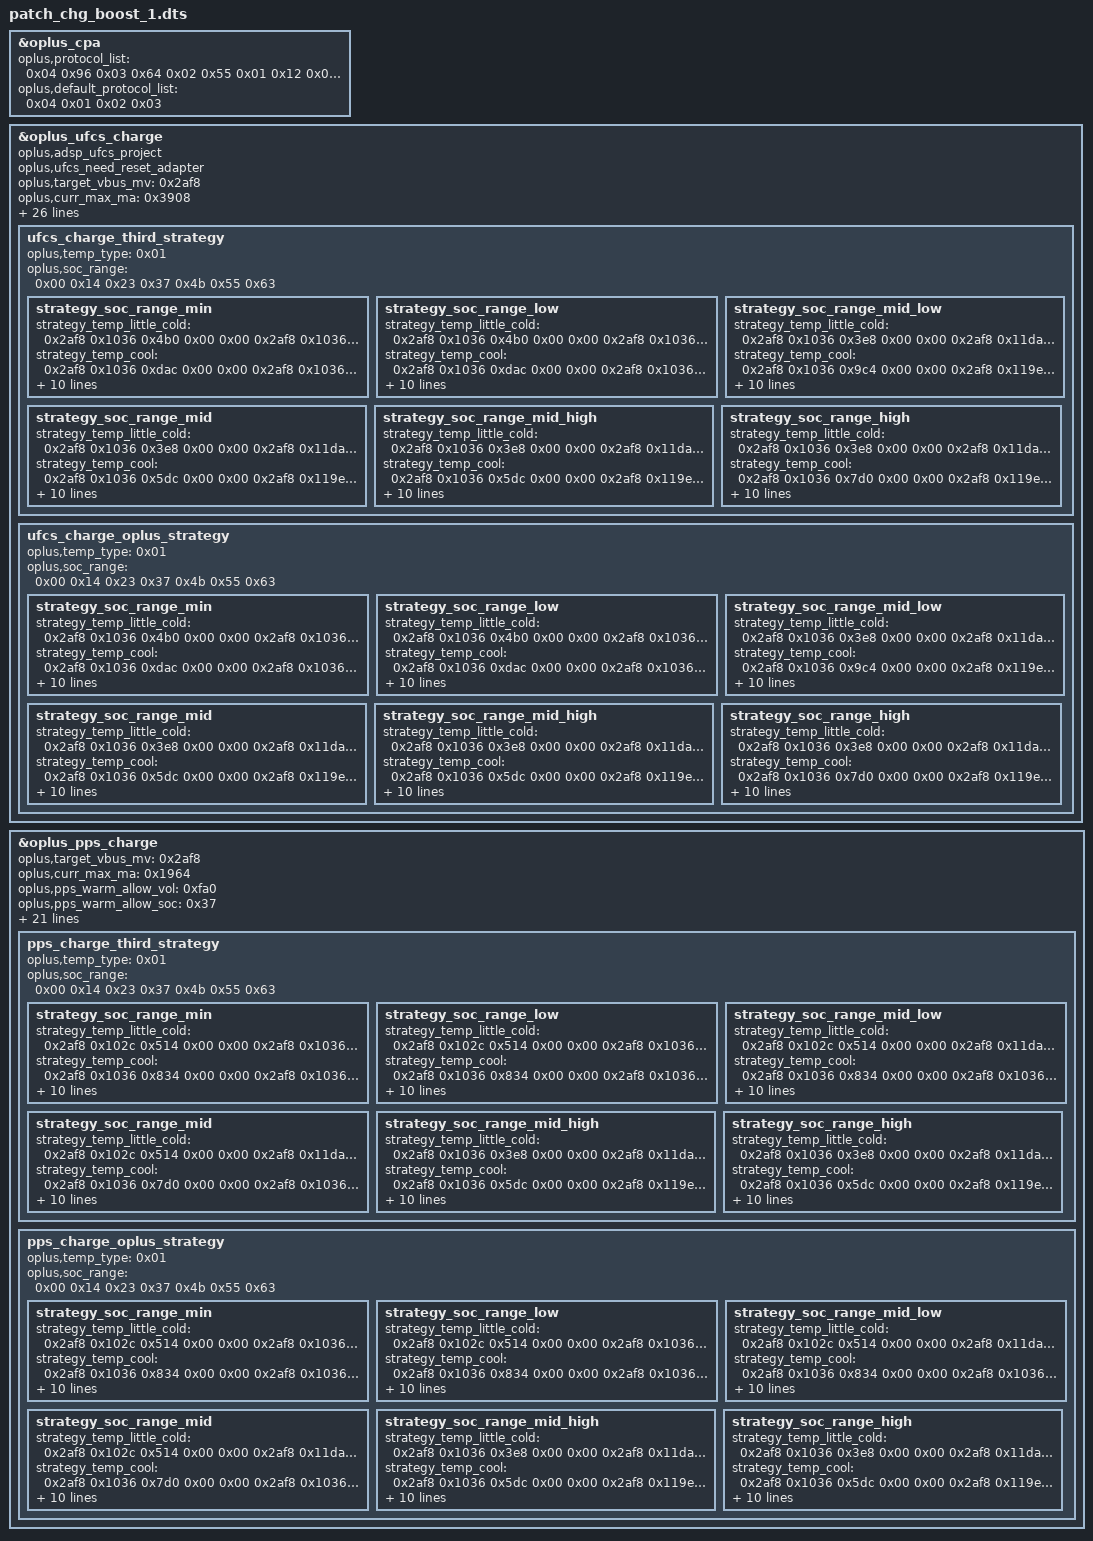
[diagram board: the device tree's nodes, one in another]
/dts-v1/;
/plugin/;

/ {
	fragment@0 {
		target = <&oplus_cpa>;
		__overlay__ {
			oplus,protocol_list = <0x04 0x96 0x03 0x64 0x02 0x55 0x01 0x12 0x05 0x12>;
			oplus,default_protocol_list = <0x04 0x01 0x02 0x03>;
		};
	};
	
	fragment@1 {
		target = <&oplus_ufcs_charge>;
		__overlay__ {
			oplus,adsp_ufcs_project;
			oplus,ufcs_need_reset_adapter;
			oplus,target_vbus_mv = <0x2af8>;
			oplus,curr_max_ma = <0x3908>;
			oplus,subboard_ntc_abnormal_current = <0x1c84>;
			oplus,ufcs_warm_allow_vol = <0xfa0>;
			oplus,ufcs_warm_allow_soc = <0x37>;
			oplus,ufcs_strategy_normal_current = <0x3908>;
			oplus,ufcs_over_high_or_low_current = <0x3908>;
			oplus,ufcs_timeout_third = <0x3a28>;
			oplus,ufcs_timeout_oplus = <0x3a28>;
			oplus,ufcs_ibat_over_third = <0x3908>;
			oplus,ufcs_ibat_over_oplus = <0x3908>;
			oplus,ufcs_ibus_over_oplus = <0x3778>;
			oplus,ufcs_full_cool_sw_vbat = <0x11f8>;
			oplus,ufcs_full_normal_sw_vbat = <0x11f8>;
			oplus,ufcs_full_normal_hw_vbat = <0x1202>;
			oplus,ufcs_full_ffc_vbat = <0x11bc>;
			oplus,ufcs_full_warm_vbat = <0x1022>;
			oplus,ufcs_full_cool_sw_vbat_third = <0x11f8>;
			oplus,ufcs_full_normal_sw_vbat_third = <0x11f8>;
			oplus,ufcs_full_normal_hw_vbat_third = <0x1202>;
			oplus,ufcs_current_change_timeout = <0x64>;
			oplus,ufcs_strategy_high_current = <0x1388 0xfa0 0xbb8 0x3908 0x1388 0xfa0>;
			oplus,ufcs_little_cool_high_temp = <0xd2>;
			oplus,curve_strategy_name = "pps_ufcs_curve_v2";
			oplus_spec,ufcs_high_soc = <0x63>;
			oplus,ufcs_charge_strategy_soc = <0x00 0x14 0x23 0x37 0x4b 0x55 0x63>;
			
			ufcs_charge_third_strategy {
				oplus,temp_type = <0x01>;
				oplus,soc_range = <0x00 0x14 0x23 0x37 0x4b 0x55 0x63>;
				
				strategy_soc_range_min {
					strategy_temp_little_cold = <0x2af8 0x1036 0x4b0 0x00 0x00 0x2af8 0x1036 0x3e8 0x00 0x00 0x2af8 0x11da 0x1f4 0x01 0x00>;
					strategy_temp_cool = <0x2af8 0x1036 0xdac 0x00 0x00 0x2af8 0x1036 0xbb8 0x00 0x00 0x2af8 0x119e 0x4b0 0x00 0x00 0x2af8 0x119e 0x3e8 0x00 0x00 0x2af8 0x11d0 0x258 0x00 0x00 0x2af8 0x11da 0x1f4 0x01 0x00>;
					strategy_temp_little_cool = <0x2af8 0x1036 0x1194 0x00 0x00 0x2af8 0x1036 0xdac 0x00 0x00 0x2af8 0x10ea 0xbb8 0x00 0x00 0x2af8 0x10ea 0x9c4 0x00 0x00 0x2af8 0x11d0 0x4b0 0x00 0x00 0x2af8 0x11d0 0x3e8 0x00 0x00 0x2af8 0x11da 0x2bc 0x01 0x00>;
					strategy_temp_little_cool_high = <0x2af8 0x1068 0x1964 0x00 0x00 0x2af8 0x1068 0x1770 0x00 0x00 0x2af8 0x1068 0x157c 0x00 0x00 0x2af8 0x1068 0x1194 0x00 0x00 0x2af8 0x10ea 0x1194 0x00 0x00 0x2af8 0x10ea 0xfa0 0x00 0x00 0x2af8 0x119e 0xc1c 0x00 0x00 0x2af8 0x119e 0xbb8 0x00 0x00 0x2af8 0x11d0 0xa28 0x00 0x00 0x2af8 0x11d0 0x9c4 0x00 0x00 0x2af8 0x11d0 0x7d0 0x00 0x00 0x2af8 0x11d0 0x5dc 0x00 0x00 0x2af8 0x11d0 0x3e8 0x00 0x00 0x2af8 0x11da 0x320 0x01 0x00>;
					strategy_temp_normal_low = <0x2af8 0x1054 0x238c 0x00 0x00 0x2af8 0x1054 0x238c 0x00 0x00 0x2af8 0x1054 0x238c 0x00 0x00 0x2af8 0x1086 0x238c 0x00 0x00 0x2af8 0x1086 0x2328 0x00 0x00 0x2af8 0x1086 0x2134 0x00 0x00 0x2af8 0x1108 0x1f40 0x00 0x00 0x2af8 0x1108 0x1b58 0x00 0x00 0x2af8 0x1108 0x1770 0x00 0x00 0x2af8 0x1108 0x157c 0x00 0x00 0x2af8 0x1180 0x1450 0x00 0x00 0x2af8 0x1180 0x1388 0x00 0x00 0x2af8 0x1180 0x1194 0x00 0x00 0x2af8 0x1180 0xfa0 0x00 0x00 0x2af8 0x11b2 0xf3c 0x00 0x00 0x2af8 0x11b2 0xdac 0x00 0x00 0x2af8 0x11d0 0xc1c 0x00 0x00 0x2af8 0x11d0 0xbb8 0x00 0x00 0x2af8 0x11d0 0x9c4 0x00 0x00 0x2af8 0x11d0 0x7d0 0x00 0x00 0x2af8 0x11d0 0x5dc 0x00 0x00 0x2af8 0x11da 0x578 0x01 0x00>;
					strategy_temp_normal_high = <0x2af8 0x1054 0x238c 0x00 0x00 0x2af8 0x1054 0x238c 0x00 0x00 0x2af8 0x1054 0x238c 0x00 0x00 0x2af8 0x1086 0x238c 0x00 0x00 0x2af8 0x1086 0x2134 0x00 0x00 0x2af8 0x1086 0x206c 0x00 0x00 0x2af8 0x1108 0x1f40 0x00 0x00 0x2af8 0x1108 0x1d4c 0x00 0x00 0x2af8 0x1108 0x1964 0x00 0x00 0x2af8 0x1108 0x157c 0x00 0x00 0x2af8 0x1180 0x1450 0x00 0x00 0x2af8 0x1180 0x1388 0x00 0x00 0x2af8 0x1180 0x1194 0x00 0x00 0x2af8 0x1180 0xfa0 0x00 0x00 0x2af8 0x11b2 0xf3c 0x00 0x00 0x2af8 0x11b2 0xdac 0x00 0x00 0x2af8 0x11d0 0xc1c 0x00 0x00 0x2af8 0x11d0 0xbb8 0x00 0x00 0x2af8 0x11d0 0x9c4 0x00 0x00 0x2af8 0x11d0 0x7d0 0x00 0x00 0x2af8 0x11da 0x76c 0x01 0x00>;
					strategy_temp_warm = <0x2af8 0x1018 0x578 0x00 0x00 0x2af8 0x1018 0x3e8 0x00 0x00 0x2af8 0x1022 0x1f4 0x01 0x00>;
				};
				
				strategy_soc_range_low {
					strategy_temp_little_cold = <0x2af8 0x1036 0x4b0 0x00 0x00 0x2af8 0x1036 0x3e8 0x00 0x00 0x2af8 0x11da 0x1f4 0x01 0x00>;
					strategy_temp_cool = <0x2af8 0x1036 0xdac 0x00 0x00 0x2af8 0x1036 0xdac 0x00 0x00 0x2af8 0x119e 0x4b0 0x00 0x00 0x2af8 0x119e 0x3e8 0x00 0x00 0x2af8 0x11d0 0x258 0x00 0x00 0x2af8 0x11da 0x1f4 0x01 0x00>;
					strategy_temp_little_cool = <0x2af8 0x1036 0xdac 0x00 0x00 0x2af8 0x1036 0xbb8 0x00 0x00 0x2af8 0x10ea 0x9c4 0x00 0x00 0x2af8 0x10ea 0x7d0 0x00 0x00 0x2af8 0x11d0 0x4b0 0x00 0x00 0x2af8 0x11d0 0x3e8 0x00 0x00 0x2af8 0x11da 0x2bc 0x01 0x00>;
					strategy_temp_little_cool_high = <0x2af8 0x1068 0x1d4c 0x00 0x00 0x2af8 0x1068 0x1964 0x00 0x00 0x2af8 0x1068 0x1770 0x00 0x00 0x2af8 0x1068 0x157c 0x00 0x00 0x2af8 0x10ea 0x1388 0x00 0x00 0x2af8 0x10ea 0x1194 0x00 0x00 0x2af8 0x119e 0xc1c 0x00 0x00 0x2af8 0x119e 0xbb8 0x00 0x00 0x2af8 0x11d0 0xa28 0x00 0x00 0x2af8 0x11d0 0x9c4 0x00 0x00 0x2af8 0x11d0 0x7d0 0x00 0x00 0x2af8 0x11d0 0x5dc 0x00 0x00 0x2af8 0x11d0 0x3e8 0x00 0x00 0x2af8 0x11da 0x320 0x01 0x00>;
					strategy_temp_normal_low = <0x2af8 0x1054 0x238c 0x00 0x00 0x2af8 0x1054 0x238c 0x00 0x00 0x2af8 0x1054 0x238c 0x00 0x00 0x2af8 0x1086 0x22c4 0x00 0x00 0x2af8 0x1108 0x1f40 0x00 0x00 0x2af8 0x1108 0x1b58 0x00 0x00 0x2af8 0x1108 0x1964 0x00 0x00 0x2af8 0x1108 0x157c 0x00 0x00 0x2af8 0x1180 0x1450 0x00 0x00 0x2af8 0x1180 0x1388 0x00 0x00 0x2af8 0x1180 0x1194 0x00 0x00 0x2af8 0x1180 0xfa0 0x00 0x00 0x2af8 0x11b2 0xf3c 0x00 0x00 0x2af8 0x11b2 0xdac 0x00 0x00 0x2af8 0x11d0 0xc1c 0x00 0x00 0x2af8 0x11d0 0xbb8 0x00 0x00 0x2af8 0x11d0 0x9c4 0x00 0x00 0x2af8 0x11d0 0x7d0 0x00 0x00 0x2af8 0x11d0 0x5dc 0x00 0x00 0x2af8 0x11da 0x578 0x01 0x00>;
					strategy_temp_normal_high = <0x2af8 0x1054 0x238c 0x00 0x00 0x2af8 0x1054 0x238c 0x00 0x00 0x2af8 0x1054 0x2134 0x00 0x00 0x2af8 0x1086 0x2134 0x00 0x00 0x2af8 0x1086 0x2134 0x00 0x00 0x2af8 0x1086 0x1f40 0x00 0x00 0x2af8 0x1108 0x1d4c 0x00 0x00 0x2af8 0x1108 0x1a2c 0x00 0x00 0x2af8 0x1108 0x1964 0x00 0x00 0x2af8 0x1108 0x157c 0x00 0x00 0x2af8 0x1180 0x1450 0x00 0x00 0x2af8 0x1180 0x1388 0x00 0x00 0x2af8 0x1180 0x1194 0x00 0x00 0x2af8 0x1180 0xfa0 0x00 0x00 0x2af8 0x11b2 0xf3c 0x00 0x00 0x2af8 0x11b2 0xdac 0x00 0x00 0x2af8 0x11d0 0xc1c 0x00 0x00 0x2af8 0x11d0 0xbb8 0x00 0x00 0x2af8 0x11d0 0x9c4 0x00 0x00 0x2af8 0x11d0 0x7d0 0x00 0x00 0x2af8 0x11da 0x76c 0x01 0x00>;
					strategy_temp_warm = <0x2af8 0x1018 0x578 0x00 0x00 0x2af8 0x1018 0x3e8 0x00 0x00 0x2af8 0x1022 0x1f4 0x01 0x00>;
				};
				
				strategy_soc_range_mid_low {
					strategy_temp_little_cold = <0x2af8 0x1036 0x3e8 0x00 0x00 0x2af8 0x11da 0x1f4 0x01 0x00>;
					strategy_temp_cool = <0x2af8 0x1036 0x9c4 0x00 0x00 0x2af8 0x119e 0x4b0 0x00 0x00 0x2af8 0x119e 0x3e8 0x00 0x00 0x2af8 0x11d0 0x258 0x00 0x00 0x2af8 0x11da 0x1f4 0x01 0x00>;
					strategy_temp_little_cool = <0x2af8 0x1036 0x1194 0x00 0x00 0x2af8 0x1036 0x1194 0x00 0x00 0x2af8 0x10ea 0x7d0 0x00 0x00 0x2af8 0x10ea 0x5dc 0x00 0x00 0x2af8 0x11d0 0x4b0 0x00 0x00 0x2af8 0x11d0 0x3e8 0x00 0x00 0x2af8 0x11da 0x2bc 0x01 0x00>;
					strategy_temp_little_cool_high = <0x2af8 0x1068 0x1964 0x00 0x00 0x2af8 0x1068 0x1964 0x00 0x00 0x2af8 0x1068 0x157c 0x00 0x00 0x2af8 0x1068 0x1194 0x00 0x00 0x2af8 0x10ea 0xf3c 0x00 0x00 0x2af8 0x10ea 0xdac 0x00 0x00 0x2af8 0x119e 0xc1c 0x00 0x00 0x2af8 0x119e 0xbb8 0x00 0x00 0x2af8 0x11d0 0xa28 0x00 0x00 0x2af8 0x11d0 0x9c4 0x00 0x00 0x2af8 0x11d0 0x7d0 0x00 0x00 0x2af8 0x11d0 0x5dc 0x00 0x00 0x2af8 0x11d0 0x3e8 0x00 0x00 0x2af8 0x11da 0x320 0x01 0x00>;
					strategy_temp_normal_low = <0x2af8 0x1054 0x238c 0x00 0x00 0x2af8 0x1054 0x238c 0x00 0x00 0x2af8 0x1054 0x238c 0x00 0x00 0x2af8 0x1086 0x2134 0x00 0x00 0x2af8 0x1086 0x2134 0x00 0x00 0x2af8 0x1086 0x1f40 0x00 0x00 0x2af8 0x1108 0x1e78 0x00 0x00 0x2af8 0x1108 0x1ce8 0x00 0x00 0x2af8 0x1108 0x1964 0x00 0x00 0x2af8 0x1108 0x1770 0x00 0x00 0x2af8 0x1180 0x1450 0x00 0x00 0x2af8 0x1180 0x1388 0x00 0x00 0x2af8 0x1180 0x1194 0x00 0x00 0x2af8 0x1180 0xfa0 0x00 0x00 0x2af8 0x11b2 0xf3c 0x00 0x00 0x2af8 0x11b2 0xdac 0x00 0x00 0x2af8 0x11d0 0xc1c 0x00 0x00 0x2af8 0x11d0 0xbb8 0x00 0x00 0x2af8 0x11d0 0x9c4 0x00 0x00 0x2af8 0x11d0 0x7d0 0x00 0x00 0x2af8 0x11d0 0x5dc 0x00 0x00 0x2af8 0x11da 0x578 0x01 0x00>;
					strategy_temp_normal_high = <0x2af8 0x1054 0x238c 0x00 0x00 0x2af8 0x1054 0x238c 0x00 0x00 0x2af8 0x1054 0x238c 0x00 0x00 0x2af8 0x1086 0x238c 0x00 0x00 0x2af8 0x1086 0x2260 0x00 0x00 0x2af8 0x1086 0x2134 0x00 0x00 0x2af8 0x1108 0x1d4c 0x00 0x00 0x2af8 0x1108 0x1b58 0x00 0x00 0x2af8 0x1108 0x1964 0x00 0x00 0x2af8 0x1108 0x16a8 0x00 0x00 0x2af8 0x1180 0x1450 0x00 0x00 0x2af8 0x1180 0x1388 0x00 0x00 0x2af8 0x1180 0x1194 0x00 0x00 0x2af8 0x1180 0xfa0 0x00 0x00 0x2af8 0x11b2 0xf3c 0x00 0x00 0x2af8 0x11b2 0xdac 0x00 0x00 0x2af8 0x11d0 0xc1c 0x00 0x00 0x2af8 0x11d0 0xbb8 0x00 0x00 0x2af8 0x11d0 0x9c4 0x00 0x00 0x2af8 0x11d0 0x7d0 0x00 0x00 0x2af8 0x11da 0x76c 0x01 0x00>;
					strategy_temp_warm = <0x2af8 0x1018 0x578 0x00 0x00 0x2af8 0x1018 0x3e8 0x00 0x00 0x2af8 0x1022 0x1f4 0x01 0x00>;
				};
				
				strategy_soc_range_mid {
					strategy_temp_little_cold = <0x2af8 0x1036 0x3e8 0x00 0x00 0x2af8 0x11da 0x1f4 0x01 0x00>;
					strategy_temp_cool = <0x2af8 0x1036 0x5dc 0x00 0x00 0x2af8 0x119e 0x4b0 0x00 0x00 0x2af8 0x119e 0x3e8 0x00 0x00 0x2af8 0x11d0 0x258 0x00 0x00 0x2af8 0x11da 0x1f4 0x01 0x00>;
					strategy_temp_little_cool = <0x2af8 0x1036 0xa28 0x00 0x00 0x2af8 0x1036 0x9c4 0x00 0x00 0x2af8 0x10ea 0x7d0 0x00 0x00 0x2af8 0x10ea 0x5dc 0x00 0x00 0x2af8 0x11d0 0x4b0 0x00 0x00 0x2af8 0x11d0 0x3e8 0x00 0x00 0x2af8 0x11da 0x2bc 0x01 0x00>;
					strategy_temp_little_cool_high = <0x2af8 0x1068 0x1d4c 0x00 0x00 0x2af8 0x1086 0x1c84 0x00 0x00 0x2af8 0x1108 0x1c20 0x00 0x00 0x2af8 0x1108 0x1b58 0x00 0x00 0x2af8 0x1108 0x1964 0x00 0x00 0x2af8 0x1108 0x16a8 0x00 0x00 0x2af8 0x10ea 0x1194 0x00 0x00 0x2af8 0x10ea 0x1068 0x00 0x00 0x2af8 0x119e 0xc1c 0x00 0x00 0x2af8 0x119e 0xbb8 0x00 0x00 0x2af8 0x11d0 0xa28 0x00 0x00 0x2af8 0x11d0 0x9c4 0x00 0x00 0x2af8 0x11d0 0x7d0 0x00 0x00 0x2af8 0x11d0 0x5dc 0x00 0x00 0x2af8 0x11d0 0x3e8 0x00 0x00 0x2af8 0x11da 0x320 0x01 0x00>;
					strategy_temp_normal_low = <0x2af8 0x1068 0x1d4c 0x00 0x00 0x2af8 0x1086 0x1c84 0x00 0x00 0x2af8 0x1108 0x1c20 0x00 0x00 0x2af8 0x1108 0x1b58 0x00 0x00 0x2af8 0x1108 0x1964 0x00 0x00 0x2af8 0x1108 0x1770 0x00 0x00 0x2af8 0x10ea 0x157c 0x00 0x00 0x2af8 0x10ea 0x14b4 0x00 0x00 0x2af8 0x1180 0x1388 0x00 0x00 0x2af8 0x1180 0x10cc 0x00 0x00 0x2af8 0x11b2 0xf3c 0x00 0x00 0x2af8 0x11b2 0xf3c 0x00 0x00 0x2af8 0x11d0 0xdac 0x00 0x00 0x2af8 0x11d0 0xbb8 0x00 0x00 0x2af8 0x11d0 0x9c4 0x00 0x00 0x2af8 0x11d0 0x7d0 0x00 0x00 0x2af8 0x11d0 0x5dc 0x00 0x00 0x2af8 0x11da 0x578 0x01 0x00>;
					strategy_temp_normal_high = <0x2af8 0x1108 0x1964 0x00 0x00 0x2af8 0x1108 0x1770 0x00 0x00 0x2af8 0x10ea 0x157c 0x00 0x00 0x2af8 0x10ea 0x14b4 0x00 0x00 0x2af8 0x1180 0x1388 0x00 0x00 0x2af8 0x1180 0x1194 0x00 0x00 0x2af8 0x1180 0xfa0 0x00 0x00 0x2af8 0x11b2 0xf3c 0x00 0x00 0x2af8 0x11b2 0xdac 0x00 0x00 0x2af8 0x11d0 0xc1c 0x00 0x00 0x2af8 0x11d0 0xbb8 0x00 0x00 0x2af8 0x11d0 0x9c4 0x00 0x00 0x2af8 0x11d0 0x7d0 0x00 0x00 0x2af8 0x11da 0x76c 0x01 0x00>;
					strategy_temp_warm = <0x2af8 0x1022 0x3e8 0x01 0x00>;
				};
				
				strategy_soc_range_mid_high {
					strategy_temp_little_cold = <0x2af8 0x1036 0x3e8 0x00 0x00 0x2af8 0x11da 0x1f4 0x01 0x00>;
					strategy_temp_cool = <0x2af8 0x1036 0x5dc 0x00 0x00 0x2af8 0x119e 0x4b0 0x00 0x00 0x2af8 0x119e 0x3e8 0x00 0x00 0x2af8 0x11d0 0x258 0x00 0x00 0x2af8 0x11da 0x1f4 0x01 0x00>;
					strategy_temp_little_cool = <0x2af8 0x1036 0xbb8 0x00 0x00 0x2af8 0x1036 0xbb8 0x00 0x00 0x2af8 0x10ea 0x9c4 0x00 0x00 0x2af8 0x10ea 0x7d0 0x00 0x00 0x2af8 0x11d0 0x4b0 0x00 0x00 0x2af8 0x11d0 0x3e8 0x00 0x00 0x2af8 0x11da 0x2bc 0x01 0x00>;
					strategy_temp_little_cool_high = <0x2af8 0x119e 0xdac 0x00 0x00 0x2af8 0x11d0 0xaf0 0x00 0x00 0x2af8 0x11d0 0xa28 0x00 0x00 0x2af8 0x11d0 0x898 0x00 0x00 0x2af8 0x11d0 0x5dc 0x00 0x00 0x2af8 0x11d0 0x3e8 0x00 0x00 0x2af8 0x11da 0x320 0x01 0x00>;
					strategy_temp_normal_low = <0x2af8 0x11b2 0xe10 0x00 0x00 0x2af8 0x11d0 0xd48 0x00 0x00 0x2af8 0x11d0 0xc80 0x00 0x00 0x2af8 0x11d0 0x9c4 0x00 0x00 0x2af8 0x11d0 0x7d0 0x00 0x00 0x2af8 0x11d0 0x5dc 0x00 0x00 0x2af8 0x11da 0x578 0x01 0x00>;
					strategy_temp_normal_high = <0x2af8 0x11b2 0xce4 0x00 0x00 0x2af8 0x11d0 0xc1c 0x00 0x00 0x2af8 0x11d0 0xbb8 0x00 0x00 0x2af8 0x11d0 0x9c4 0x00 0x00 0x2af8 0x11d0 0x7d0 0x00 0x00 0x2af8 0x11da 0x76c 0x01 0x00>;
					strategy_temp_warm = <0x2af8 0x1022 0x3e8 0x01 0x00>;
				};
				
				strategy_soc_range_high {
					strategy_temp_little_cold = <0x2af8 0x1036 0x3e8 0x00 0x00 0x2af8 0x11da 0x1f4 0x01 0x00>;
					strategy_temp_cool = <0x2af8 0x1036 0x7d0 0x00 0x00 0x2af8 0x119e 0x7d0 0x00 0x00 0x2af8 0x119e 0x5dc 0x00 0x00 0x2af8 0x11d0 0x514 0x00 0x00 0x2af8 0x11da 0x3e8 0x01 0x00>;
					strategy_temp_little_cool = <0x2af8 0x10ea 0x834 0x00 0x00 0x2af8 0x11d0 0x7d0 0x00 0x00 0x2af8 0x11d0 0x44c 0x00 0x00 0x2af8 0x11da 0x3e8 0x01 0x00>;
					strategy_temp_little_cool_high = <0x2af8 0x11d0 0x834 0x00 0x00 0x2af8 0x11d0 0x7d0 0x00 0x00 0x2af8 0x11da 0x3e8 0x01 0x00>;
					strategy_temp_normal_low = <0x2af8 0x11d0 0x834 0x00 0x00 0x2af8 0x11d0 0x7d0 0x00 0x00 0x2af8 0x11da 0x3e8 0x01 0x00>;
					strategy_temp_normal_high = <0x2af8 0x11d0 0x7d0 0x00 0x00 0x2af8 0x11da 0x76c 0x01 0x00>;
					strategy_temp_warm = <0x2af8 0x1022 0x3e8 0x01 0x00>;
				};
			};
			
			ufcs_charge_oplus_strategy {
				oplus,temp_type = <0x01>;
				oplus,soc_range = <0x00 0x14 0x23 0x37 0x4b 0x55 0x63>;
				
				strategy_soc_range_min {
					strategy_temp_little_cold = <0x2af8 0x1036 0x4b0 0x00 0x00 0x2af8 0x1036 0x3e8 0x00 0x00 0x2af8 0x11da 0x1f4 0x01 0x00>;
					strategy_temp_cool = <0x2af8 0x1036 0xdac 0x00 0x00 0x2af8 0x1036 0xbb8 0x00 0x00 0x2af8 0x119e 0x4b0 0x00 0x00 0x2af8 0x119e 0x3e8 0x00 0x00 0x2af8 0x11d0 0x258 0x00 0x00 0x2af8 0x11da 0x1f4 0x01 0x00>;
					strategy_temp_little_cool = <0x2af8 0x1036 0x1194 0x00 0x00 0x2af8 0x1036 0xdac 0x00 0x00 0x2af8 0x10ea 0xbb8 0x00 0x00 0x2af8 0x10ea 0x9c4 0x00 0x00 0x2af8 0x11d0 0x4b0 0x00 0x00 0x2af8 0x11d0 0x3e8 0x00 0x00 0x2af8 0x11da 0x2bc 0x01 0x00>;
					strategy_temp_little_cool_high = <0x2af8 0x1068 0x1964 0x00 0x00 0x2af8 0x1068 0x1770 0x00 0x00 0x2af8 0x1068 0x157c 0x00 0x00 0x2af8 0x1068 0x1194 0x00 0x00 0x2af8 0x10ea 0x1194 0x00 0x00 0x2af8 0x10ea 0xfa0 0x00 0x00 0x2af8 0x119e 0xc1c 0x00 0x00 0x2af8 0x119e 0xbb8 0x00 0x00 0x2af8 0x11d0 0xa28 0x00 0x00 0x2af8 0x11d0 0x9c4 0x00 0x00 0x2af8 0x11d0 0x7d0 0x00 0x00 0x2af8 0x11d0 0x5dc 0x00 0x00 0x2af8 0x11d0 0x3e8 0x00 0x00 0x2af8 0x11da 0x320 0x01 0x00>;
					strategy_temp_normal_low = <0x2af8 0x1054 0x238c 0x00 0x00 0x2af8 0x1054 0x238c 0x00 0x00 0x2af8 0x1054 0x238c 0x00 0x00 0x2af8 0x1086 0x238c 0x00 0x00 0x2af8 0x1086 0x2328 0x00 0x00 0x2af8 0x1086 0x2134 0x00 0x00 0x2af8 0x1108 0x1f40 0x00 0x00 0x2af8 0x1108 0x1b58 0x00 0x00 0x2af8 0x1108 0x1770 0x00 0x00 0x2af8 0x1108 0x157c 0x00 0x00 0x2af8 0x1180 0x1450 0x00 0x00 0x2af8 0x1180 0x1388 0x00 0x00 0x2af8 0x1180 0x1194 0x00 0x00 0x2af8 0x1180 0xfa0 0x00 0x00 0x2af8 0x11b2 0xf3c 0x00 0x00 0x2af8 0x11b2 0xdac 0x00 0x00 0x2af8 0x11d0 0xc1c 0x00 0x00 0x2af8 0x11d0 0xbb8 0x00 0x00 0x2af8 0x11d0 0x9c4 0x00 0x00 0x2af8 0x11d0 0x7d0 0x00 0x00 0x2af8 0x11d0 0x5dc 0x00 0x00 0x2af8 0x11da 0x578 0x01 0x00>;
					strategy_temp_normal_high = <0x2af8 0x1054 0x238c 0x00 0x00 0x2af8 0x1054 0x238c 0x00 0x00 0x2af8 0x1054 0x238c 0x00 0x00 0x2af8 0x1086 0x238c 0x00 0x00 0x2af8 0x1086 0x2134 0x00 0x00 0x2af8 0x1086 0x206c 0x00 0x00 0x2af8 0x1108 0x1f40 0x00 0x00 0x2af8 0x1108 0x1d4c 0x00 0x00 0x2af8 0x1108 0x1964 0x00 0x00 0x2af8 0x1108 0x157c 0x00 0x00 0x2af8 0x1180 0x1450 0x00 0x00 0x2af8 0x1180 0x1388 0x00 0x00 0x2af8 0x1180 0x1194 0x00 0x00 0x2af8 0x1180 0xfa0 0x00 0x00 0x2af8 0x11b2 0xf3c 0x00 0x00 0x2af8 0x11b2 0xdac 0x00 0x00 0x2af8 0x11d0 0xc1c 0x00 0x00 0x2af8 0x11d0 0xbb8 0x00 0x00 0x2af8 0x11d0 0x9c4 0x00 0x00 0x2af8 0x11d0 0x7d0 0x00 0x00 0x2af8 0x11da 0x76c 0x01 0x00>;
					strategy_temp_warm = <0x2af8 0x1018 0x578 0x00 0x00 0x2af8 0x1018 0x3e8 0x00 0x00 0x2af8 0x1022 0x1f4 0x01 0x00>;
				};
				
				strategy_soc_range_low {
					strategy_temp_little_cold = <0x2af8 0x1036 0x4b0 0x00 0x00 0x2af8 0x1036 0x3e8 0x00 0x00 0x2af8 0x11da 0x1f4 0x01 0x00>;
					strategy_temp_cool = <0x2af8 0x1036 0xdac 0x00 0x00 0x2af8 0x1036 0xdac 0x00 0x00 0x2af8 0x119e 0x4b0 0x00 0x00 0x2af8 0x119e 0x3e8 0x00 0x00 0x2af8 0x11d0 0x258 0x00 0x00 0x2af8 0x11da 0x1f4 0x01 0x00>;
					strategy_temp_little_cool = <0x2af8 0x1036 0xdac 0x00 0x00 0x2af8 0x1036 0xbb8 0x00 0x00 0x2af8 0x10ea 0x9c4 0x00 0x00 0x2af8 0x10ea 0x7d0 0x00 0x00 0x2af8 0x11d0 0x4b0 0x00 0x00 0x2af8 0x11d0 0x3e8 0x00 0x00 0x2af8 0x11da 0x2bc 0x01 0x00>;
					strategy_temp_little_cool_high = <0x2af8 0x1068 0x1d4c 0x00 0x00 0x2af8 0x1068 0x1964 0x00 0x00 0x2af8 0x1068 0x1770 0x00 0x00 0x2af8 0x1068 0x157c 0x00 0x00 0x2af8 0x10ea 0x1388 0x00 0x00 0x2af8 0x10ea 0x1194 0x00 0x00 0x2af8 0x119e 0xc1c 0x00 0x00 0x2af8 0x119e 0xbb8 0x00 0x00 0x2af8 0x11d0 0xa28 0x00 0x00 0x2af8 0x11d0 0x9c4 0x00 0x00 0x2af8 0x11d0 0x7d0 0x00 0x00 0x2af8 0x11d0 0x5dc 0x00 0x00 0x2af8 0x11d0 0x3e8 0x00 0x00 0x2af8 0x11da 0x320 0x01 0x00>;
					strategy_temp_normal_low = <0x2af8 0x1054 0x238c 0x00 0x00 0x2af8 0x1054 0x238c 0x00 0x00 0x2af8 0x1054 0x238c 0x00 0x00 0x2af8 0x1086 0x22c4 0x00 0x00 0x2af8 0x1108 0x1f40 0x00 0x00 0x2af8 0x1108 0x1b58 0x00 0x00 0x2af8 0x1108 0x1964 0x00 0x00 0x2af8 0x1108 0x157c 0x00 0x00 0x2af8 0x1180 0x1450 0x00 0x00 0x2af8 0x1180 0x1388 0x00 0x00 0x2af8 0x1180 0x1194 0x00 0x00 0x2af8 0x1180 0xfa0 0x00 0x00 0x2af8 0x11b2 0xf3c 0x00 0x00 0x2af8 0x11b2 0xdac 0x00 0x00 0x2af8 0x11d0 0xc1c 0x00 0x00 0x2af8 0x11d0 0xbb8 0x00 0x00 0x2af8 0x11d0 0x9c4 0x00 0x00 0x2af8 0x11d0 0x7d0 0x00 0x00 0x2af8 0x11d0 0x5dc 0x00 0x00 0x2af8 0x11da 0x578 0x01 0x00>;
					strategy_temp_normal_high = <0x2af8 0x1054 0x238c 0x00 0x00 0x2af8 0x1054 0x238c 0x00 0x00 0x2af8 0x1054 0x2134 0x00 0x00 0x2af8 0x1086 0x2134 0x00 0x00 0x2af8 0x1086 0x2134 0x00 0x00 0x2af8 0x1086 0x1f40 0x00 0x00 0x2af8 0x1108 0x1d4c 0x00 0x00 0x2af8 0x1108 0x1a2c 0x00 0x00 0x2af8 0x1108 0x1964 0x00 0x00 0x2af8 0x1108 0x157c 0x00 0x00 0x2af8 0x1180 0x1450 0x00 0x00 0x2af8 0x1180 0x1388 0x00 0x00 0x2af8 0x1180 0x1194 0x00 0x00 0x2af8 0x1180 0xfa0 0x00 0x00 0x2af8 0x11b2 0xf3c 0x00 0x00 0x2af8 0x11b2 0xdac 0x00 0x00 0x2af8 0x11d0 0xc1c 0x00 0x00 0x2af8 0x11d0 0xbb8 0x00 0x00 0x2af8 0x11d0 0x9c4 0x00 0x00 0x2af8 0x11d0 0x7d0 0x00 0x00 0x2af8 0x11da 0x76c 0x01 0x00>;
					strategy_temp_warm = <0x2af8 0x1018 0x578 0x00 0x00 0x2af8 0x1018 0x3e8 0x00 0x00 0x2af8 0x1022 0x1f4 0x01 0x00>;
				};
				
				strategy_soc_range_mid_low {
					strategy_temp_little_cold = <0x2af8 0x1036 0x3e8 0x00 0x00 0x2af8 0x11da 0x1f4 0x01 0x00>;
					strategy_temp_cool = <0x2af8 0x1036 0x9c4 0x00 0x00 0x2af8 0x119e 0x4b0 0x00 0x00 0x2af8 0x119e 0x3e8 0x00 0x00 0x2af8 0x11d0 0x258 0x00 0x00 0x2af8 0x11da 0x1f4 0x01 0x00>;
					strategy_temp_little_cool = <0x2af8 0x1036 0x1194 0x00 0x00 0x2af8 0x1036 0x1194 0x00 0x00 0x2af8 0x10ea 0x7d0 0x00 0x00 0x2af8 0x10ea 0x5dc 0x00 0x00 0x2af8 0x11d0 0x4b0 0x00 0x00 0x2af8 0x11d0 0x3e8 0x00 0x00 0x2af8 0x11da 0x2bc 0x01 0x00>;
					strategy_temp_little_cool_high = <0x2af8 0x1068 0x1964 0x00 0x00 0x2af8 0x1068 0x1964 0x00 0x00 0x2af8 0x1068 0x157c 0x00 0x00 0x2af8 0x1068 0x1194 0x00 0x00 0x2af8 0x10ea 0xf3c 0x00 0x00 0x2af8 0x10ea 0xdac 0x00 0x00 0x2af8 0x119e 0xc1c 0x00 0x00 0x2af8 0x119e 0xbb8 0x00 0x00 0x2af8 0x11d0 0xa28 0x00 0x00 0x2af8 0x11d0 0x9c4 0x00 0x00 0x2af8 0x11d0 0x7d0 0x00 0x00 0x2af8 0x11d0 0x5dc 0x00 0x00 0x2af8 0x11d0 0x3e8 0x00 0x00 0x2af8 0x11da 0x320 0x01 0x00>;
					strategy_temp_normal_low = <0x2af8 0x1054 0x238c 0x00 0x00 0x2af8 0x1054 0x238c 0x00 0x00 0x2af8 0x1054 0x238c 0x00 0x00 0x2af8 0x1086 0x2134 0x00 0x00 0x2af8 0x1086 0x2134 0x00 0x00 0x2af8 0x1086 0x1f40 0x00 0x00 0x2af8 0x1108 0x1e78 0x00 0x00 0x2af8 0x1108 0x1ce8 0x00 0x00 0x2af8 0x1108 0x1964 0x00 0x00 0x2af8 0x1108 0x1770 0x00 0x00 0x2af8 0x1180 0x1450 0x00 0x00 0x2af8 0x1180 0x1388 0x00 0x00 0x2af8 0x1180 0x1194 0x00 0x00 0x2af8 0x1180 0xfa0 0x00 0x00 0x2af8 0x11b2 0xf3c 0x00 0x00 0x2af8 0x11b2 0xdac 0x00 0x00 0x2af8 0x11d0 0xc1c 0x00 0x00 0x2af8 0x11d0 0xbb8 0x00 0x00 0x2af8 0x11d0 0x9c4 0x00 0x00 0x2af8 0x11d0 0x7d0 0x00 0x00 0x2af8 0x11d0 0x5dc 0x00 0x00 0x2af8 0x11da 0x578 0x01 0x00>;
					strategy_temp_normal_high = <0x2af8 0x1054 0x238c 0x00 0x00 0x2af8 0x1054 0x238c 0x00 0x00 0x2af8 0x1054 0x238c 0x00 0x00 0x2af8 0x1086 0x238c 0x00 0x00 0x2af8 0x1086 0x2260 0x00 0x00 0x2af8 0x1086 0x2134 0x00 0x00 0x2af8 0x1108 0x1d4c 0x00 0x00 0x2af8 0x1108 0x1b58 0x00 0x00 0x2af8 0x1108 0x1964 0x00 0x00 0x2af8 0x1108 0x16a8 0x00 0x00 0x2af8 0x1180 0x1450 0x00 0x00 0x2af8 0x1180 0x1388 0x00 0x00 0x2af8 0x1180 0x1194 0x00 0x00 0x2af8 0x1180 0xfa0 0x00 0x00 0x2af8 0x11b2 0xf3c 0x00 0x00 0x2af8 0x11b2 0xdac 0x00 0x00 0x2af8 0x11d0 0xc1c 0x00 0x00 0x2af8 0x11d0 0xbb8 0x00 0x00 0x2af8 0x11d0 0x9c4 0x00 0x00 0x2af8 0x11d0 0x7d0 0x00 0x00 0x2af8 0x11da 0x76c 0x01 0x00>;
					strategy_temp_warm = <0x2af8 0x1018 0x578 0x00 0x00 0x2af8 0x1018 0x3e8 0x00 0x00 0x2af8 0x1022 0x1f4 0x01 0x00>;
				};
				
				strategy_soc_range_mid {
					strategy_temp_little_cold = <0x2af8 0x1036 0x3e8 0x00 0x00 0x2af8 0x11da 0x1f4 0x01 0x00>;
					strategy_temp_cool = <0x2af8 0x1036 0x5dc 0x00 0x00 0x2af8 0x119e 0x4b0 0x00 0x00 0x2af8 0x119e 0x3e8 0x00 0x00 0x2af8 0x11d0 0x258 0x00 0x00 0x2af8 0x11da 0x1f4 0x01 0x00>;
					strategy_temp_little_cool = <0x2af8 0x1036 0xa28 0x00 0x00 0x2af8 0x1036 0x9c4 0x00 0x00 0x2af8 0x10ea 0x7d0 0x00 0x00 0x2af8 0x10ea 0x5dc 0x00 0x00 0x2af8 0x11d0 0x4b0 0x00 0x00 0x2af8 0x11d0 0x3e8 0x00 0x00 0x2af8 0x11da 0x2bc 0x01 0x00>;
					strategy_temp_little_cool_high = <0x2af8 0x1068 0x1d4c 0x00 0x00 0x2af8 0x1086 0x1c84 0x00 0x00 0x2af8 0x1108 0x1c20 0x00 0x00 0x2af8 0x1108 0x1b58 0x00 0x00 0x2af8 0x1108 0x1964 0x00 0x00 0x2af8 0x1108 0x16a8 0x00 0x00 0x2af8 0x10ea 0x1194 0x00 0x00 0x2af8 0x10ea 0x1068 0x00 0x00 0x2af8 0x119e 0xc1c 0x00 0x00 0x2af8 0x119e 0xbb8 0x00 0x00 0x2af8 0x11d0 0xa28 0x00 0x00 0x2af8 0x11d0 0x9c4 0x00 0x00 0x2af8 0x11d0 0x7d0 0x00 0x00 0x2af8 0x11d0 0x5dc 0x00 0x00 0x2af8 0x11d0 0x3e8 0x00 0x00 0x2af8 0x11da 0x320 0x01 0x00>;
					strategy_temp_normal_low = <0x2af8 0x1068 0x1d4c 0x00 0x00 0x2af8 0x1086 0x1c84 0x00 0x00 0x2af8 0x1108 0x1c20 0x00 0x00 0x2af8 0x1108 0x1b58 0x00 0x00 0x2af8 0x1108 0x1964 0x00 0x00 0x2af8 0x1108 0x1770 0x00 0x00 0x2af8 0x10ea 0x157c 0x00 0x00 0x2af8 0x10ea 0x14b4 0x00 0x00 0x2af8 0x1180 0x1388 0x00 0x00 0x2af8 0x1180 0x10cc 0x00 0x00 0x2af8 0x11b2 0xf3c 0x00 0x00 0x2af8 0x11b2 0xf3c 0x00 0x00 0x2af8 0x11d0 0xdac 0x00 0x00 0x2af8 0x11d0 0xbb8 0x00 0x00 0x2af8 0x11d0 0x9c4 0x00 0x00 0x2af8 0x11d0 0x7d0 0x00 0x00 0x2af8 0x11d0 0x5dc 0x00 0x00 0x2af8 0x11da 0x578 0x01 0x00>;
					strategy_temp_normal_high = <0x2af8 0x1108 0x1964 0x00 0x00 0x2af8 0x1108 0x1770 0x00 0x00 0x2af8 0x10ea 0x157c 0x00 0x00 0x2af8 0x10ea 0x14b4 0x00 0x00 0x2af8 0x1180 0x1388 0x00 0x00 0x2af8 0x1180 0x1194 0x00 0x00 0x2af8 0x1180 0xfa0 0x00 0x00 0x2af8 0x11b2 0xf3c 0x00 0x00 0x2af8 0x11b2 0xdac 0x00 0x00 0x2af8 0x11d0 0xc1c 0x00 0x00 0x2af8 0x11d0 0xbb8 0x00 0x00 0x2af8 0x11d0 0x9c4 0x00 0x00 0x2af8 0x11d0 0x7d0 0x00 0x00 0x2af8 0x11da 0x76c 0x01 0x00>;
					strategy_temp_warm = <0x2af8 0x1022 0x3e8 0x01 0x00>;
				};
				
				strategy_soc_range_mid_high {
					strategy_temp_little_cold = <0x2af8 0x1036 0x3e8 0x00 0x00 0x2af8 0x11da 0x1f4 0x01 0x00>;
					strategy_temp_cool = <0x2af8 0x1036 0x5dc 0x00 0x00 0x2af8 0x119e 0x4b0 0x00 0x00 0x2af8 0x119e 0x3e8 0x00 0x00 0x2af8 0x11d0 0x258 0x00 0x00 0x2af8 0x11da 0x1f4 0x01 0x00>;
					strategy_temp_little_cool = <0x2af8 0x1036 0xbb8 0x00 0x00 0x2af8 0x1036 0xbb8 0x00 0x00 0x2af8 0x10ea 0x9c4 0x00 0x00 0x2af8 0x10ea 0x7d0 0x00 0x00 0x2af8 0x11d0 0x4b0 0x00 0x00 0x2af8 0x11d0 0x3e8 0x00 0x00 0x2af8 0x11da 0x2bc 0x01 0x00>;
					strategy_temp_little_cool_high = <0x2af8 0x119e 0xdac 0x00 0x00 0x2af8 0x11d0 0xaf0 0x00 0x00 0x2af8 0x11d0 0xa28 0x00 0x00 0x2af8 0x11d0 0x898 0x00 0x00 0x2af8 0x11d0 0x5dc 0x00 0x00 0x2af8 0x11d0 0x3e8 0x00 0x00 0x2af8 0x11da 0x320 0x01 0x00>;
					strategy_temp_normal_low = <0x2af8 0x11b2 0xe10 0x00 0x00 0x2af8 0x11d0 0xd48 0x00 0x00 0x2af8 0x11d0 0xc80 0x00 0x00 0x2af8 0x11d0 0x9c4 0x00 0x00 0x2af8 0x11d0 0x7d0 0x00 0x00 0x2af8 0x11d0 0x5dc 0x00 0x00 0x2af8 0x11da 0x578 0x01 0x00>;
					strategy_temp_normal_high = <0x2af8 0x11b2 0xce4 0x00 0x00 0x2af8 0x11d0 0xc1c 0x00 0x00 0x2af8 0x11d0 0xbb8 0x00 0x00 0x2af8 0x11d0 0x9c4 0x00 0x00 0x2af8 0x11d0 0x7d0 0x00 0x00 0x2af8 0x11da 0x76c 0x01 0x00>;
					strategy_temp_warm = <0x2af8 0x1022 0x3e8 0x01 0x00>;
				};
				
				strategy_soc_range_high {
					strategy_temp_little_cold = <0x2af8 0x1036 0x3e8 0x00 0x00 0x2af8 0x11da 0x1f4 0x01 0x00>;
					strategy_temp_cool = <0x2af8 0x1036 0x7d0 0x00 0x00 0x2af8 0x119e 0x7d0 0x00 0x00 0x2af8 0x119e 0x5dc 0x00 0x00 0x2af8 0x11d0 0x514 0x00 0x00 0x2af8 0x11da 0x3e8 0x01 0x00>;
					strategy_temp_little_cool = <0x2af8 0x10ea 0x834 0x00 0x00 0x2af8 0x11d0 0x7d0 0x00 0x00 0x2af8 0x11d0 0x44c 0x00 0x00 0x2af8 0x11da 0x3e8 0x01 0x00>;
					strategy_temp_little_cool_high = <0x2af8 0x11d0 0x834 0x00 0x00 0x2af8 0x11d0 0x7d0 0x00 0x00 0x2af8 0x11da 0x3e8 0x01 0x00>;
					strategy_temp_normal_low = <0x2af8 0x11d0 0x834 0x00 0x00 0x2af8 0x11d0 0x7d0 0x00 0x00 0x2af8 0x11da 0x3e8 0x01 0x00>;
					strategy_temp_normal_high = <0x2af8 0x11d0 0x7d0 0x00 0x00 0x2af8 0x11da 0x76c 0x01 0x00>;
					strategy_temp_warm = <0x2af8 0x1022 0x3e8 0x01 0x00>;
				};
			};
		};
	};
	
	fragment@2{
		target = <&oplus_pps_charge>;
		__overlay__ {
			oplus,target_vbus_mv = <0x2af8>;
			oplus,curr_max_ma = <0x1964>;
			oplus,pps_warm_allow_vol = <0xfa0>;
			oplus,pps_warm_allow_soc = <0x37>;
			oplus,pps_strategy_normal_current = <0x1964>;
			oplus,pps_over_high_or_low_current = <0xbb8>;
			oplus,pps_timeout_third = <0x3a28>;
			oplus,pps_timeout_oplus = <0x3a28>;
			oplus,pps_ibat_over_third = <0x1964>;
			oplus,pps_ibat_over_oplus = <0x1964>;
			oplus,pps_full_cool_sw_vbat = <0x11f8>;
			oplus,pps_full_normal_sw_vbat = <0x11f8>;
			oplus,pps_full_normal_hw_vbat = <0x1202>;
			oplus,pps_full_ffc_vbat = <0x11c6>;
			oplus,pps_full_warm_vbat = <0x1022>;
			oplus,pps_full_cool_sw_vbat_third = <0x11f8>;
			oplus,pps_full_normal_sw_vbat_third = <0x11f8>;
			oplus,pps_full_normal_hw_vbat_third = <0x1202>;
			oplus,pps_current_change_timeout = <0x64>;
			oplus,pps_strategy_high_current = <0x1964 0x1964 0x1964 0x1964 0x1964 0x1964>;
			oplus,pps_little_cool_high_temp = <0xd2>;
			oplus,curve_strategy_name = "pps_ufcs_curve_v2";
			oplus,pps_charge_strategy_soc = <0x00 0x14 0x23 0x37 0x4b 0x55 0x63>;
			
			pps_charge_third_strategy {
				oplus,temp_type = <0x01>;
				oplus,soc_range = <0x00 0x14 0x23 0x37 0x4b 0x55 0x63>;
				
				strategy_soc_range_min {
					strategy_temp_little_cold = <0x2af8 0x102c 0x514 0x00 0x00 0x2af8 0x1036 0x3e8 0x01 0x00>;
					strategy_temp_cool = <0x2af8 0x1036 0x834 0x00 0x00 0x2af8 0x1036 0x7d0 0x00 0x00 0x2af8 0x1036 0x5dc 0x00 0x00 0x2af8 0x119e 0x4b0 0x00 0x00 0x2af8 0x119e 0x3e8 0x00 0x00 0x2af8 0x11d0 0x258 0x00 0x00 0x2af8 0x11da 0x1f4 0x01 0x00>;
					strategy_temp_little_cool = <0x2af8 0x1036 0xed8 0x00 0x00 0x2af8 0x1036 0xe74 0x00 0x00 0x2af8 0x10ea 0xdac 0x00 0x00 0x2af8 0x10ea 0xbb8 0x00 0x00 0x2af8 0x10ea 0x7d0 0x00 0x00 0x2af8 0x11d0 0x514 0x00 0x00 0x2af8 0x11da 0x3e8 0x01 0x00>;
					strategy_temp_little_cool_high = <0x2af8 0x1036 0x1964 0x00 0x00 0x2af8 0x1036 0x1964 0x00 0x00 0x2af8 0x10b8 0x1964 0x00 0x00 0x2af8 0x10b8 0x12c0 0x00 0x00 0x2af8 0x10ea 0xfa0 0x00 0x00 0x2af8 0x119e 0xc1c 0x00 0x00 0x2af8 0x119e 0xbb8 0x00 0x00 0x2af8 0x11d0 0xa28 0x00 0x00 0x2af8 0x11d0 0x9c4 0x00 0x00 0x2af8 0x11d0 0x7d0 0x00 0x00 0x2af8 0x11d0 0x5dc 0x00 0x00 0x2af8 0x11d0 0x3e8 0x00 0x00 0x2af8 0x11da 0x320 0x01 0x00>;
					strategy_temp_normal_low = <0x2af8 0x1176 0x1964 0x00 0x00 0x2af8 0x1176 0x1964 0x00 0x00 0x2af8 0x1176 0x1964 0x00 0x00 0x2af8 0x1180 0x1450 0x00 0x00 0x2af8 0x1180 0x1964 0x00 0x00 0x2af8 0x1180 0x1194 0x00 0x00 0x2af8 0x1180 0xfa0 0x00 0x00 0x2af8 0x11b2 0xf3c 0x00 0x00 0x2af8 0x11b2 0xdac 0x00 0x00 0x2af8 0x11d0 0xc1c 0x00 0x00 0x2af8 0x11d0 0xbb8 0x00 0x00 0x2af8 0x11d0 0x9c4 0x00 0x00 0x2af8 0x11d0 0x7d0 0x00 0x00 0x2af8 0x11d0 0x5dc 0x00 0x00 0x2af8 0x11da 0x578 0x01 0x00>;
					strategy_temp_normal_high = <0x2af8 0x1176 0x1964 0x00 0x00 0x2af8 0x1176 0x1964 0x00 0x00 0x2af8 0x1176 0x1964 0x00 0x00 0x2af8 0x1180 0x1450 0x00 0x00 0x2af8 0x1180 0x1964 0x00 0x00 0x2af8 0x1180 0x1194 0x00 0x00 0x2af8 0x1180 0xfa0 0x00 0x00 0x2af8 0x11b2 0xf3c 0x00 0x00 0x2af8 0x11b2 0xdac 0x00 0x00 0x2af8 0x11d0 0xc1c 0x00 0x00 0x2af8 0x11d0 0xbb8 0x00 0x00 0x2af8 0x11d0 0x9c4 0x00 0x00 0x2af8 0x11d0 0x7d0 0x00 0x00 0x2af8 0x11da 0x76c 0x01 0x00>;
					strategy_temp_warm = <0x2af8 0x1018 0x5dc 0x00 0x00 0x2af8 0x1022 0x3e8 0x01 0x00>;
				};
				
				strategy_soc_range_low {
					strategy_temp_little_cold = <0x2af8 0x102c 0x514 0x00 0x00 0x2af8 0x1036 0x3e8 0x01 0x00>;
					strategy_temp_cool = <0x2af8 0x1036 0x834 0x00 0x00 0x2af8 0x1036 0xdac 0x00 0x00 0x2af8 0x119e 0x4b0 0x00 0x00 0x2af8 0x119e 0x3e8 0x00 0x00 0x2af8 0x11d0 0x258 0x00 0x00 0x2af8 0x11da 0x1f4 0x01 0x00>;
					strategy_temp_little_cool = <0x2af8 0x1036 0xdac 0x00 0x00 0x2af8 0x1036 0xbb8 0x00 0x00 0x2af8 0x10ea 0x9c4 0x00 0x00 0x2af8 0x10ea 0x7d0 0x00 0x00 0x2af8 0x11d0 0x4b0 0x00 0x00 0x2af8 0x11d0 0x3e8 0x00 0x00 0x2af8 0x11da 0x2bc 0x01 0x00>;
					strategy_temp_little_cool_high = <0x2af8 0x1036 0x1964 0x00 0x00 0x2af8 0x1036 0x1964 0x00 0x00 0x2af8 0x10b8 0x1964 0x00 0x00 0x2af8 0x10b8 0x1964 0x00 0x00 0x2af8 0x10ea 0x1964 0x00 0x00 0x2af8 0x10ea 0x1194 0x00 0x00 0x2af8 0x119e 0xc1c 0x00 0x00 0x2af8 0x119e 0xbb8 0x00 0x00 0x2af8 0x11d0 0xa28 0x00 0x00 0x2af8 0x11d0 0x9c4 0x00 0x00 0x2af8 0x11d0 0x7d0 0x00 0x00 0x2af8 0x11d0 0x5dc 0x00 0x00 0x2af8 0x11d0 0x3e8 0x00 0x00 0x2af8 0x11da 0x320 0x01 0x00>;
					strategy_temp_normal_low = <0x2af8 0x1176 0x1964 0x00 0x00 0x2af8 0x1176 0x1964 0x00 0x00 0x2af8 0x1176 0x1964 0x00 0x00 0x2af8 0x118a 0x1964 0x00 0x00 0x2af8 0x1180 0x1450 0x00 0x00 0x2af8 0x1180 0x1964 0x00 0x00 0x2af8 0x1180 0x1194 0x00 0x00 0x2af8 0x1180 0xfa0 0x00 0x00 0x2af8 0x11b2 0xf3c 0x00 0x00 0x2af8 0x11b2 0xdac 0x00 0x00 0x2af8 0x11d0 0xc1c 0x00 0x00 0x2af8 0x11d0 0xbb8 0x00 0x00 0x2af8 0x11d0 0x9c4 0x00 0x00 0x2af8 0x11d0 0x7d0 0x00 0x00 0x2af8 0x11d0 0x5dc 0x00 0x00 0x2af8 0x11da 0x578 0x01 0x00>;
					strategy_temp_normal_high = <0x2af8 0x1176 0x1964 0x00 0x00 0x2af8 0x1176 0x1964 0x00 0x00 0x2af8 0x1176 0x1194 0x00 0x00 0x2af8 0x1180 0x1450 0x00 0x00 0x2af8 0x1180 0x1964 0x00 0x00 0x2af8 0x1180 0x1194 0x00 0x00 0x2af8 0x1180 0xfa0 0x00 0x00 0x2af8 0x11b2 0xf3c 0x00 0x00 0x2af8 0x11b2 0xdac 0x00 0x00 0x2af8 0x11d0 0xc1c 0x00 0x00 0x2af8 0x11d0 0xbb8 0x00 0x00 0x2af8 0x11d0 0x9c4 0x00 0x00 0x2af8 0x11d0 0x7d0 0x00 0x00 0x2af8 0x11da 0x76c 0x01 0x00>;
					strategy_temp_warm = <0x2af8 0x1018 0x5dc 0x00 0x00 0x2af8 0x1022 0x3e8 0x01 0x00>;
				};
				
				strategy_soc_range_mid_low {
					strategy_temp_little_cold = <0x2af8 0x102c 0x514 0x00 0x00 0x2af8 0x11da 0x1f4 0x01 0x00>;
					strategy_temp_cool = <0x2af8 0x1036 0x834 0x00 0x00 0x2af8 0x1036 0x7d0 0x00 0x00 0x2af8 0x1036 0x5dc 0x00 0x00 0x2af8 0x118a 0x514 0x00 0x00 0x2af8 0x11da 0x3e8 0x01 0x00>;
					strategy_temp_little_cool = <0x2af8 0x1036 0xdac 0x00 0x00 0x2af8 0x1036 0xdac 0x00 0x00 0x2af8 0x10ea 0xdac 0x00 0x00 0x2af8 0x10ea 0xbb8 0x00 0x00 0x2af8 0x10ea 0xaf0 0x00 0x00 0x2af8 0x118a 0x514 0x00 0x00 0x2af8 0x11da 0x3e8 0x01 0x00>;
					strategy_temp_little_cool_high = <0x2af8 0x1068 0x1964 0x00 0x00 0x2af8 0x1068 0x1194 0x00 0x00 0x2af8 0x10ea 0xf3c 0x00 0x00 0x2af8 0x10ea 0xdac 0x00 0x00 0x2af8 0x119e 0xc1c 0x00 0x00 0x2af8 0x119e 0xbb8 0x00 0x00 0x2af8 0x11d0 0xa28 0x00 0x00 0x2af8 0x11d0 0x9c4 0x00 0x00 0x2af8 0x11d0 0x7d0 0x00 0x00 0x2af8 0x11d0 0x5dc 0x00 0x00 0x2af8 0x11d0 0x3e8 0x00 0x00 0x2af8 0x11da 0x320 0x01 0x00>;
					strategy_temp_normal_low = <0x2af8 0x1108 0x1964 0x00 0x00 0x2af8 0x1180 0x1964 0x00 0x00 0x2af8 0x1180 0x1964 0x00 0x00 0x2af8 0x1180 0x1194 0x00 0x00 0x2af8 0x1180 0xfa0 0x00 0x00 0x2af8 0x11b2 0xf3c 0x00 0x00 0x2af8 0x11b2 0xdac 0x00 0x00 0x2af8 0x11d0 0xc1c 0x00 0x00 0x2af8 0x11d0 0xbb8 0x00 0x00 0x2af8 0x11d0 0x9c4 0x00 0x00 0x2af8 0x11d0 0x7d0 0x00 0x00 0x2af8 0x11d0 0x5dc 0x00 0x00 0x2af8 0x11da 0x578 0x01 0x00>;
					strategy_temp_normal_high = <0x2af8 0x1180 0x1964 0x00 0x00 0x2af8 0x1180 0x1964 0x00 0x00 0x2af8 0x1180 0x1194 0x00 0x00 0x2af8 0x1180 0x1068 0x00 0x00 0x2af8 0x11b2 0xfa0 0x00 0x00 0x2af8 0x11b2 0xfa0 0x00 0x00 0x2af8 0x11b2 0xf3c 0x00 0x00 0x2af8 0x11b2 0xdac 0x00 0x00 0x2af8 0x11d0 0xc1c 0x00 0x00 0x2af8 0x11d0 0xbb8 0x00 0x00 0x2af8 0x11d0 0x9c4 0x00 0x00 0x2af8 0x11d0 0x7d0 0x00 0x00 0x2af8 0x11da 0x76c 0x01 0x00>;
					strategy_temp_warm = <0x2af8 0x1018 0x5dc 0x00 0x00 0x2af8 0x1022 0x3e8 0x01 0x00>;
				};
				
				strategy_soc_range_mid {
					strategy_temp_little_cold = <0x2af8 0x102c 0x514 0x00 0x00 0x2af8 0x11da 0x1f4 0x01 0x00>;
					strategy_temp_cool = <0x2af8 0x1036 0x7d0 0x00 0x00 0x2af8 0x1036 0x5dc 0x00 0x00 0x2af8 0x118a 0x514 0x00 0x00 0x2af8 0x11da 0x3e8 0x01 0x00>;
					strategy_temp_little_cool = <0x2af8 0x1036 0xfa0 0x00 0x00 0x2af8 0x1036 0xfa0 0x00 0x00 0x2af8 0x10ea 0xbb8 0x00 0x00 0x2af8 0x10ea 0x9c4 0x00 0x00 0x2af8 0x10ea 0x7d0 0x00 0x00 0x2af8 0x118a 0x514 0x00 0x00 0x2af8 0x11da 0x3e8 0x01 0x00>;
					strategy_temp_little_cool_high = <0x2af8 0x10e0 0x1964 0x00 0x00 0x2af8 0x10ea 0x1194 0x00 0x00 0x2af8 0x10ea 0x1068 0x00 0x00 0x2af8 0x119e 0xc1c 0x00 0x00 0x2af8 0x119e 0xbb8 0x00 0x00 0x2af8 0x11d0 0xa28 0x00 0x00 0x2af8 0x11d0 0x9c4 0x00 0x00 0x2af8 0x11d0 0x7d0 0x00 0x00 0x2af8 0x11d0 0x5dc 0x00 0x00 0x2af8 0x11d0 0x3e8 0x00 0x00 0x2af8 0x11da 0x320 0x01 0x00>;
					strategy_temp_normal_low = <0x2af8 0x1108 0x1964 0x00 0x00 0x2af8 0x10ea 0x1964 0x00 0x00 0x2af8 0x10ea 0x1964 0x00 0x00 0x2af8 0x1180 0x1964 0x00 0x00 0x2af8 0x1180 0x10cc 0x00 0x00 0x2af8 0x11b2 0xf3c 0x00 0x00 0x2af8 0x11b2 0xf3c 0x00 0x00 0x2af8 0x11d0 0xdac 0x00 0x00 0x2af8 0x11d0 0xbb8 0x00 0x00 0x2af8 0x11d0 0x9c4 0x00 0x00 0x2af8 0x11d0 0x7d0 0x00 0x00 0x2af8 0x11d0 0x5dc 0x00 0x00 0x2af8 0x11da 0x578 0x01 0x00>;
					strategy_temp_normal_high = <0x2af8 0x1180 0x1964 0x00 0x00 0x2af8 0x1180 0x1194 0x00 0x00 0x2af8 0x1180 0xfa0 0x00 0x00 0x2af8 0x11b2 0xf3c 0x00 0x00 0x2af8 0x11b2 0xdac 0x00 0x00 0x2af8 0x11d0 0xc1c 0x00 0x00 0x2af8 0x11d0 0xbb8 0x00 0x00 0x2af8 0x11d0 0x9c4 0x00 0x00 0x2af8 0x11d0 0x7d0 0x00 0x00 0x2af8 0x11da 0x76c 0x01 0x00>;
					strategy_temp_warm = <0x2af8 0x1022 0x3e8 0x01 0x00>;
				};
				
				strategy_soc_range_mid_high {
					strategy_temp_little_cold = <0x2af8 0x1036 0x3e8 0x00 0x00 0x2af8 0x11da 0x1f4 0x01 0x00>;
					strategy_temp_cool = <0x2af8 0x1036 0x5dc 0x00 0x00 0x2af8 0x119e 0x4b0 0x00 0x00 0x2af8 0x119e 0x3e8 0x00 0x00 0x2af8 0x11d0 0x258 0x00 0x00 0x2af8 0x11da 0x1f4 0x01 0x00>;
					strategy_temp_little_cool = <0x2af8 0x1036 0xbb8 0x00 0x00 0x2af8 0x1036 0xbb8 0x00 0x00 0x2af8 0x10ea 0x9c4 0x00 0x00 0x2af8 0x10ea 0x7d0 0x00 0x00 0x2af8 0x11d0 0x4b0 0x00 0x00 0x2af8 0x11d0 0x3e8 0x00 0x00 0x2af8 0x11da 0x2bc 0x01 0x00>;
					strategy_temp_little_cool_high = <0x2af8 0x1180 0xc80 0x00 0x00 0x2af8 0x118a 0xbb8 0x00 0x00 0x2af8 0x11da 0xaf0 0x00 0x00 0x2af8 0x11d0 0x9c4 0x00 0x00 0x2af8 0x11d0 0x7d0 0x00 0x00 0x2af8 0x11d0 0x5dc 0x00 0x00 0x2af8 0x11da 0x320 0x01 0x00>;
					strategy_temp_normal_low = <0x2af8 0x118a 0xc80 0x00 0x00 0x2af8 0x11c6 0xbb8 0x00 0x00 0x2af8 0x11d0 0xaf0 0x00 0x00 0x2af8 0x11d0 0x9c4 0x00 0x00 0x2af8 0x11d0 0x7d0 0x00 0x00 0x2af8 0x11d0 0x5dc 0x00 0x00 0x2af8 0x11da 0x578 0x01 0x00>;
					strategy_temp_normal_high = <0x2af8 0x118a 0xc1c 0x00 0x00 0x2af8 0x11a8 0xc1c 0x00 0x00 0x2af8 0x11d0 0xbb8 0x00 0x00 0x2af8 0x11d0 0x9c4 0x00 0x00 0x2af8 0x11d0 0x7d0 0x00 0x00 0x2af8 0x11da 0x76c 0x01 0x00>;
					strategy_temp_warm = <0x2af8 0x1022 0x3e8 0x01 0x00>;
				};
				
				strategy_soc_range_high {
					strategy_temp_little_cold = <0x2af8 0x1036 0x3e8 0x00 0x00 0x2af8 0x11da 0x1f4 0x01 0x00>;
					strategy_temp_cool = <0x2af8 0x1036 0x5dc 0x00 0x00 0x2af8 0x119e 0x4b0 0x00 0x00 0x2af8 0x119e 0x3e8 0x00 0x00 0x2af8 0x11d0 0x258 0x00 0x00 0x2af8 0x11da 0x1f4 0x01 0x00>;
					strategy_temp_little_cool = <0x2af8 0x10ea 0x5dc 0x00 0x00 0x2af8 0x11d0 0x4b0 0x00 0x00 0x2af8 0x11d0 0x3e8 0x00 0x00 0x2af8 0x11da 0x2bc 0x01 0x00>;
					strategy_temp_little_cool_high = <0x2af8 0x11d0 0x5dc 0x00 0x00 0x2af8 0x11d0 0x3e8 0x00 0x00 0x2af8 0x11da 0x320 0x01 0x00>;
					strategy_temp_normal_low = <0x2af8 0x11d0 0x7d0 0x00 0x00 0x2af8 0x11d0 0x5dc 0x00 0x00 0x2af8 0x11da 0x578 0x01 0x00>;
					strategy_temp_normal_high = <0x2af8 0x11d0 0x7d0 0x00 0x00 0x2af8 0x11da 0x76c 0x01 0x00>;
					strategy_temp_warm = <0x2af8 0x1022 0x3e8 0x01 0x00>;
				};
			};
			
			pps_charge_oplus_strategy {
				oplus,temp_type = <0x01>;
				oplus,soc_range = <0x00 0x14 0x23 0x37 0x4b 0x55 0x63>;
				
				strategy_soc_range_min {
					strategy_temp_little_cold = <0x2af8 0x102c 0x514 0x00 0x00 0x2af8 0x1036 0x3e8 0x01 0x00>;
					strategy_temp_cool = <0x2af8 0x1036 0x834 0x00 0x00 0x2af8 0x1036 0x7d0 0x00 0x00 0x2af8 0x1036 0x5dc 0x00 0x00 0x2af8 0x119e 0x4b0 0x00 0x00 0x2af8 0x119e 0x3e8 0x00 0x00 0x2af8 0x11d0 0x258 0x00 0x00 0x2af8 0x11da 0x1f4 0x01 0x00>;
					strategy_temp_little_cool = <0x2af8 0x1036 0xed8 0x00 0x00 0x2af8 0x1036 0xe74 0x00 0x00 0x2af8 0x10ea 0xdac 0x00 0x00 0x2af8 0x10ea 0xbb8 0x00 0x00 0x2af8 0x10ea 0x7d0 0x00 0x00 0x2af8 0x11d0 0x514 0x00 0x00 0x2af8 0x11da 0x3e8 0x01 0x00>;
					strategy_temp_little_cool_high = <0x2af8 0x1036 0x1964 0x00 0x00 0x2af8 0x1036 0x1964 0x00 0x00 0x2af8 0x10b8 0x1964 0x00 0x00 0x2af8 0x10b8 0x12c0 0x00 0x00 0x2af8 0x10ea 0xfa0 0x00 0x00 0x2af8 0x119e 0xc1c 0x00 0x00 0x2af8 0x119e 0xbb8 0x00 0x00 0x2af8 0x11d0 0xa28 0x00 0x00 0x2af8 0x11d0 0x9c4 0x00 0x00 0x2af8 0x11d0 0x7d0 0x00 0x00 0x2af8 0x11d0 0x5dc 0x00 0x00 0x2af8 0x11d0 0x3e8 0x00 0x00 0x2af8 0x11da 0x320 0x01 0x00>;
					strategy_temp_normal_low = <0x2af8 0x1176 0x1964 0x00 0x00 0x2af8 0x1176 0x1964 0x00 0x00 0x2af8 0x1176 0x1964 0x00 0x00 0x2af8 0x1180 0x1450 0x00 0x00 0x2af8 0x1180 0x1964 0x00 0x00 0x2af8 0x1180 0x1194 0x00 0x00 0x2af8 0x1180 0xfa0 0x00 0x00 0x2af8 0x11b2 0xf3c 0x00 0x00 0x2af8 0x11b2 0xdac 0x00 0x00 0x2af8 0x11d0 0xc1c 0x00 0x00 0x2af8 0x11d0 0xbb8 0x00 0x00 0x2af8 0x11d0 0x9c4 0x00 0x00 0x2af8 0x11d0 0x7d0 0x00 0x00 0x2af8 0x11d0 0x5dc 0x00 0x00 0x2af8 0x11da 0x578 0x01 0x00>;
					strategy_temp_normal_high = <0x2af8 0x1176 0x1964 0x00 0x00 0x2af8 0x1176 0x1964 0x00 0x00 0x2af8 0x1176 0x1964 0x00 0x00 0x2af8 0x1180 0x1450 0x00 0x00 0x2af8 0x1180 0x1964 0x00 0x00 0x2af8 0x1180 0x1194 0x00 0x00 0x2af8 0x1180 0xfa0 0x00 0x00 0x2af8 0x11b2 0xf3c 0x00 0x00 0x2af8 0x11b2 0xdac 0x00 0x00 0x2af8 0x11d0 0xc1c 0x00 0x00 0x2af8 0x11d0 0xbb8 0x00 0x00 0x2af8 0x11d0 0x9c4 0x00 0x00 0x2af8 0x11d0 0x7d0 0x00 0x00 0x2af8 0x11da 0x76c 0x01 0x00>;
					strategy_temp_warm = <0x2af8 0x1018 0x5dc 0x00 0x00 0x2af8 0x1022 0x3e8 0x01 0x00>;
				};
				
				strategy_soc_range_low {
					strategy_temp_little_cold = <0x2af8 0x102c 0x514 0x00 0x00 0x2af8 0x1036 0x3e8 0x01 0x00>;
					strategy_temp_cool = <0x2af8 0x1036 0x834 0x00 0x00 0x2af8 0x1036 0xdac 0x00 0x00 0x2af8 0x119e 0x4b0 0x00 0x00 0x2af8 0x119e 0x3e8 0x00 0x00 0x2af8 0x11d0 0x258 0x00 0x00 0x2af8 0x11da 0x1f4 0x01 0x00>;
					strategy_temp_little_cool = <0x2af8 0x1036 0xdac 0x00 0x00 0x2af8 0x1036 0xbb8 0x00 0x00 0x2af8 0x10ea 0x9c4 0x00 0x00 0x2af8 0x10ea 0x7d0 0x00 0x00 0x2af8 0x11d0 0x4b0 0x00 0x00 0x2af8 0x11d0 0x3e8 0x00 0x00 0x2af8 0x11da 0x2bc 0x01 0x00>;
					strategy_temp_little_cool_high = <0x2af8 0x1036 0x1964 0x00 0x00 0x2af8 0x1036 0x1964 0x00 0x00 0x2af8 0x10b8 0x1964 0x00 0x00 0x2af8 0x10b8 0x1964 0x00 0x00 0x2af8 0x10ea 0x1964 0x00 0x00 0x2af8 0x10ea 0x1194 0x00 0x00 0x2af8 0x119e 0xc1c 0x00 0x00 0x2af8 0x119e 0xbb8 0x00 0x00 0x2af8 0x11d0 0xa28 0x00 0x00 0x2af8 0x11d0 0x9c4 0x00 0x00 0x2af8 0x11d0 0x7d0 0x00 0x00 0x2af8 0x11d0 0x5dc 0x00 0x00 0x2af8 0x11d0 0x3e8 0x00 0x00 0x2af8 0x11da 0x320 0x01 0x00>;
					strategy_temp_normal_low = <0x2af8 0x1176 0x1964 0x00 0x00 0x2af8 0x1176 0x1964 0x00 0x00 0x2af8 0x1176 0x1964 0x00 0x00 0x2af8 0x118a 0x1964 0x00 0x00 0x2af8 0x1180 0x1450 0x00 0x00 0x2af8 0x1180 0x1964 0x00 0x00 0x2af8 0x1180 0x1194 0x00 0x00 0x2af8 0x1180 0xfa0 0x00 0x00 0x2af8 0x11b2 0xf3c 0x00 0x00 0x2af8 0x11b2 0xdac 0x00 0x00 0x2af8 0x11d0 0xc1c 0x00 0x00 0x2af8 0x11d0 0xbb8 0x00 0x00 0x2af8 0x11d0 0x9c4 0x00 0x00 0x2af8 0x11d0 0x7d0 0x00 0x00 0x2af8 0x11d0 0x5dc 0x00 0x00 0x2af8 0x11da 0x578 0x01 0x00>;
					strategy_temp_normal_high = <0x2af8 0x1176 0x1964 0x00 0x00 0x2af8 0x1176 0x1964 0x00 0x00 0x2af8 0x1176 0x1194 0x00 0x00 0x2af8 0x1180 0x1450 0x00 0x00 0x2af8 0x1180 0x1964 0x00 0x00 0x2af8 0x1180 0x1194 0x00 0x00 0x2af8 0x1180 0xfa0 0x00 0x00 0x2af8 0x11b2 0xf3c 0x00 0x00 0x2af8 0x11b2 0xdac 0x00 0x00 0x2af8 0x11d0 0xc1c 0x00 0x00 0x2af8 0x11d0 0xbb8 0x00 0x00 0x2af8 0x11d0 0x9c4 0x00 0x00 0x2af8 0x11d0 0x7d0 0x00 0x00 0x2af8 0x11da 0x76c 0x01 0x00>;
					strategy_temp_warm = <0x2af8 0x1018 0x5dc 0x00 0x00 0x2af8 0x1022 0x3e8 0x01 0x00>;
				};
				
				strategy_soc_range_mid_low {
					strategy_temp_little_cold = <0x2af8 0x102c 0x514 0x00 0x00 0x2af8 0x11da 0x1f4 0x01 0x00>;
					strategy_temp_cool = <0x2af8 0x1036 0x834 0x00 0x00 0x2af8 0x1036 0x7d0 0x00 0x00 0x2af8 0x1036 0x5dc 0x00 0x00 0x2af8 0x118a 0x514 0x00 0x00 0x2af8 0x11da 0x3e8 0x01 0x00>;
					strategy_temp_little_cool = <0x2af8 0x1036 0xdac 0x00 0x00 0x2af8 0x1036 0xdac 0x00 0x00 0x2af8 0x10ea 0xdac 0x00 0x00 0x2af8 0x10ea 0xbb8 0x00 0x00 0x2af8 0x10ea 0xaf0 0x00 0x00 0x2af8 0x118a 0x514 0x00 0x00 0x2af8 0x11da 0x3e8 0x01 0x00>;
					strategy_temp_little_cool_high = <0x2af8 0x1068 0x1964 0x00 0x00 0x2af8 0x1068 0x1194 0x00 0x00 0x2af8 0x10ea 0xf3c 0x00 0x00 0x2af8 0x10ea 0xdac 0x00 0x00 0x2af8 0x119e 0xc1c 0x00 0x00 0x2af8 0x119e 0xbb8 0x00 0x00 0x2af8 0x11d0 0xa28 0x00 0x00 0x2af8 0x11d0 0x9c4 0x00 0x00 0x2af8 0x11d0 0x7d0 0x00 0x00 0x2af8 0x11d0 0x5dc 0x00 0x00 0x2af8 0x11d0 0x3e8 0x00 0x00 0x2af8 0x11da 0x320 0x01 0x00>;
					strategy_temp_normal_low = <0x2af8 0x1108 0x1964 0x00 0x00 0x2af8 0x1180 0x1964 0x00 0x00 0x2af8 0x1180 0x1964 0x00 0x00 0x2af8 0x1180 0x1194 0x00 0x00 0x2af8 0x1180 0xfa0 0x00 0x00 0x2af8 0x11b2 0xf3c 0x00 0x00 0x2af8 0x11b2 0xdac 0x00 0x00 0x2af8 0x11d0 0xc1c 0x00 0x00 0x2af8 0x11d0 0xbb8 0x00 0x00 0x2af8 0x11d0 0x9c4 0x00 0x00 0x2af8 0x11d0 0x7d0 0x00 0x00 0x2af8 0x11d0 0x5dc 0x00 0x00 0x2af8 0x11da 0x578 0x01 0x00>;
					strategy_temp_normal_high = <0x2af8 0x1180 0x1964 0x00 0x00 0x2af8 0x1180 0x1964 0x00 0x00 0x2af8 0x1180 0x1194 0x00 0x00 0x2af8 0x1180 0x1068 0x00 0x00 0x2af8 0x11b2 0xfa0 0x00 0x00 0x2af8 0x11b2 0xfa0 0x00 0x00 0x2af8 0x11b2 0xf3c 0x00 0x00 0x2af8 0x11b2 0xdac 0x00 0x00 0x2af8 0x11d0 0xc1c 0x00 0x00 0x2af8 0x11d0 0xbb8 0x00 0x00 0x2af8 0x11d0 0x9c4 0x00 0x00 0x2af8 0x11d0 0x7d0 0x00 0x00 0x2af8 0x11da 0x76c 0x01 0x00>;
					strategy_temp_warm = <0x2af8 0x1018 0x5dc 0x00 0x00 0x2af8 0x1022 0x3e8 0x01 0x00>;
				};
				
				strategy_soc_range_mid {
					strategy_temp_little_cold = <0x2af8 0x102c 0x514 0x00 0x00 0x2af8 0x11da 0x1f4 0x01 0x00>;
					strategy_temp_cool = <0x2af8 0x1036 0x7d0 0x00 0x00 0x2af8 0x1036 0x5dc 0x00 0x00 0x2af8 0x118a 0x514 0x00 0x00 0x2af8 0x11da 0x3e8 0x01 0x00>;
					strategy_temp_little_cool = <0x2af8 0x1036 0xfa0 0x00 0x00 0x2af8 0x1036 0xfa0 0x00 0x00 0x2af8 0x10ea 0xbb8 0x00 0x00 0x2af8 0x10ea 0x9c4 0x00 0x00 0x2af8 0x10ea 0x7d0 0x00 0x00 0x2af8 0x118a 0x514 0x00 0x00 0x2af8 0x11da 0x3e8 0x01 0x00>;
					strategy_temp_little_cool_high = <0x2af8 0x10e0 0x1964 0x00 0x00 0x2af8 0x10ea 0x1194 0x00 0x00 0x2af8 0x10ea 0x1068 0x00 0x00 0x2af8 0x119e 0xc1c 0x00 0x00 0x2af8 0x119e 0xbb8 0x00 0x00 0x2af8 0x11d0 0xa28 0x00 0x00 0x2af8 0x11d0 0x9c4 0x00 0x00 0x2af8 0x11d0 0x7d0 0x00 0x00 0x2af8 0x11d0 0x5dc 0x00 0x00 0x2af8 0x11d0 0x3e8 0x00 0x00 0x2af8 0x11da 0x320 0x01 0x00>;
					strategy_temp_normal_low = <0x2af8 0x1108 0x1964 0x00 0x00 0x2af8 0x10ea 0x1964 0x00 0x00 0x2af8 0x10ea 0x1964 0x00 0x00 0x2af8 0x1180 0x1964 0x00 0x00 0x2af8 0x1180 0x10cc 0x00 0x00 0x2af8 0x11b2 0xf3c 0x00 0x00 0x2af8 0x11b2 0xf3c 0x00 0x00 0x2af8 0x11d0 0xdac 0x00 0x00 0x2af8 0x11d0 0xbb8 0x00 0x00 0x2af8 0x11d0 0x9c4 0x00 0x00 0x2af8 0x11d0 0x7d0 0x00 0x00 0x2af8 0x11d0 0x5dc 0x00 0x00 0x2af8 0x11da 0x578 0x01 0x00>;
					strategy_temp_normal_high = <0x2af8 0x1180 0x1964 0x00 0x00 0x2af8 0x1180 0x1194 0x00 0x00 0x2af8 0x1180 0xfa0 0x00 0x00 0x2af8 0x11b2 0xf3c 0x00 0x00 0x2af8 0x11b2 0xdac 0x00 0x00 0x2af8 0x11d0 0xc1c 0x00 0x00 0x2af8 0x11d0 0xbb8 0x00 0x00 0x2af8 0x11d0 0x9c4 0x00 0x00 0x2af8 0x11d0 0x7d0 0x00 0x00 0x2af8 0x11da 0x76c 0x01 0x00>;
					strategy_temp_warm = <0x2af8 0x1022 0x3e8 0x01 0x00>;
				};
				
				strategy_soc_range_mid_high {
					strategy_temp_little_cold = <0x2af8 0x1036 0x3e8 0x00 0x00 0x2af8 0x11da 0x1f4 0x01 0x00>;
					strategy_temp_cool = <0x2af8 0x1036 0x5dc 0x00 0x00 0x2af8 0x119e 0x4b0 0x00 0x00 0x2af8 0x119e 0x3e8 0x00 0x00 0x2af8 0x11d0 0x258 0x00 0x00 0x2af8 0x11da 0x1f4 0x01 0x00>;
					strategy_temp_little_cool = <0x2af8 0x1036 0xbb8 0x00 0x00 0x2af8 0x1036 0xbb8 0x00 0x00 0x2af8 0x10ea 0x9c4 0x00 0x00 0x2af8 0x10ea 0x7d0 0x00 0x00 0x2af8 0x11d0 0x4b0 0x00 0x00 0x2af8 0x11d0 0x3e8 0x00 0x00 0x2af8 0x11da 0x2bc 0x01 0x00>;
					strategy_temp_little_cool_high = <0x2af8 0x1180 0xc80 0x00 0x00 0x2af8 0x118a 0xbb8 0x00 0x00 0x2af8 0x11da 0xaf0 0x00 0x00 0x2af8 0x11d0 0x9c4 0x00 0x00 0x2af8 0x11d0 0x7d0 0x00 0x00 0x2af8 0x11d0 0x5dc 0x00 0x00 0x2af8 0x11da 0x320 0x01 0x00>;
					strategy_temp_normal_low = <0x2af8 0x118a 0xc80 0x00 0x00 0x2af8 0x11c6 0xbb8 0x00 0x00 0x2af8 0x11d0 0xaf0 0x00 0x00 0x2af8 0x11d0 0x9c4 0x00 0x00 0x2af8 0x11d0 0x7d0 0x00 0x00 0x2af8 0x11d0 0x5dc 0x00 0x00 0x2af8 0x11da 0x578 0x01 0x00>;
					strategy_temp_normal_high = <0x2af8 0x118a 0xc1c 0x00 0x00 0x2af8 0x11a8 0xc1c 0x00 0x00 0x2af8 0x11d0 0xbb8 0x00 0x00 0x2af8 0x11d0 0x9c4 0x00 0x00 0x2af8 0x11d0 0x7d0 0x00 0x00 0x2af8 0x11da 0x76c 0x01 0x00>;
					strategy_temp_warm = <0x2af8 0x1022 0x3e8 0x01 0x00>;
				};
				
				strategy_soc_range_high {
					strategy_temp_little_cold = <0x2af8 0x1036 0x3e8 0x00 0x00 0x2af8 0x11da 0x1f4 0x01 0x00>;
					strategy_temp_cool = <0x2af8 0x1036 0x5dc 0x00 0x00 0x2af8 0x119e 0x4b0 0x00 0x00 0x2af8 0x119e 0x3e8 0x00 0x00 0x2af8 0x11d0 0x258 0x00 0x00 0x2af8 0x11da 0x1f4 0x01 0x00>;
					strategy_temp_little_cool = <0x2af8 0x10ea 0x5dc 0x00 0x00 0x2af8 0x11d0 0x4b0 0x00 0x00 0x2af8 0x11d0 0x3e8 0x00 0x00 0x2af8 0x11da 0x2bc 0x01 0x00>;
					strategy_temp_little_cool_high = <0x2af8 0x11d0 0x5dc 0x00 0x00 0x2af8 0x11d0 0x3e8 0x00 0x00 0x2af8 0x11da 0x320 0x01 0x00>;
					strategy_temp_normal_low = <0x2af8 0x11d0 0x7d0 0x00 0x00 0x2af8 0x11d0 0x5dc 0x00 0x00 0x2af8 0x11da 0x578 0x01 0x00>;
					strategy_temp_normal_high = <0x2af8 0x11d0 0x7d0 0x00 0x00 0x2af8 0x11da 0x76c 0x01 0x00>;
					strategy_temp_warm = <0x2af8 0x1022 0x3e8 0x01 0x00>;
				};
			};
		};
	};
};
